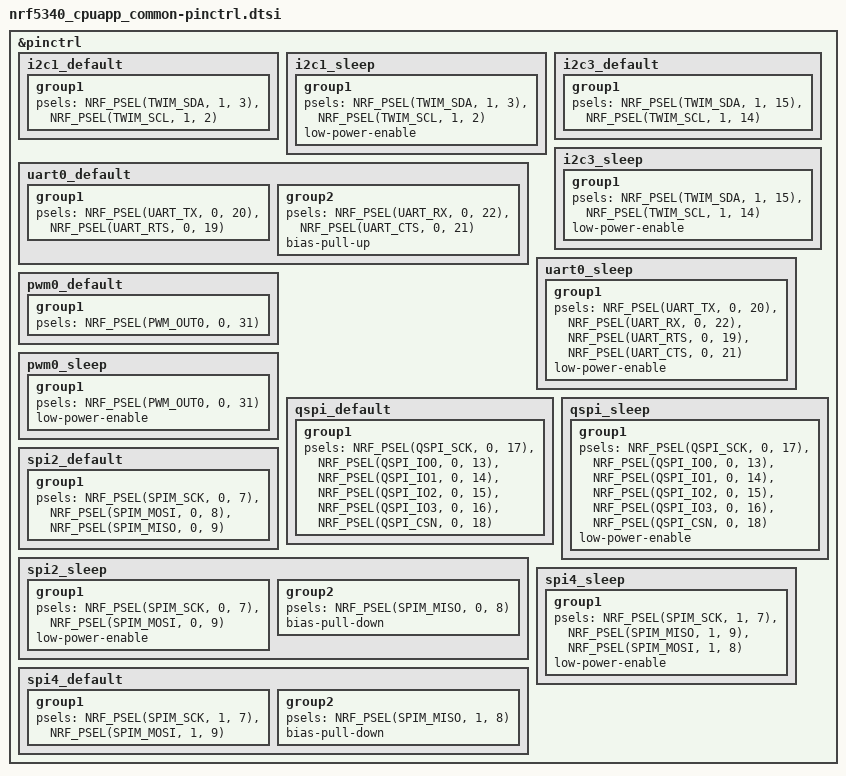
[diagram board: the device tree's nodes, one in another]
/*
 * Copyright (c) 2022 Nordic Semiconductor
 * SPDX-License-Identifier: Apache-2.0
 */

&pinctrl {
	i2c1_default: i2c1_default {
		group1 {
			psels = <NRF_PSEL(TWIM_SDA, 1, 3)>,
				<NRF_PSEL(TWIM_SCL, 1, 2)>;
		};
	};

	i2c1_sleep: i2c1_sleep {
		group1 {
			psels = <NRF_PSEL(TWIM_SDA, 1, 3)>,
				<NRF_PSEL(TWIM_SCL, 1, 2)>;
			low-power-enable;
		};
	};

	i2c3_default: i2c3_default {
		group1 {
			psels = <NRF_PSEL(TWIM_SDA, 1, 15)>,
				<NRF_PSEL(TWIM_SCL, 1, 14)>;
		};
	};

	i2c3_sleep: i2c3_sleep {
		group1 {
			psels = <NRF_PSEL(TWIM_SDA, 1, 15)>,
				<NRF_PSEL(TWIM_SCL, 1, 14)>;
			low-power-enable;
		};
	};

	uart0_default: uart0_default {
		group1 {
			psels = <NRF_PSEL(UART_TX, 0, 20)>,
				<NRF_PSEL(UART_RTS, 0, 19)>;
		};
		group2 {
			psels = <NRF_PSEL(UART_RX, 0, 22)>,
				<NRF_PSEL(UART_CTS, 0, 21)>;
			bias-pull-up;
		};
	};

	uart0_sleep: uart0_sleep {
		group1 {
			psels = <NRF_PSEL(UART_TX, 0, 20)>,
				<NRF_PSEL(UART_RX, 0, 22)>,
				<NRF_PSEL(UART_RTS, 0, 19)>,
				<NRF_PSEL(UART_CTS, 0, 21)>;
			low-power-enable;
		};
	};

	pwm0_default: pwm0_default {
		group1 {
			psels = <NRF_PSEL(PWM_OUT0, 0, 31)>;
		};
	};

	pwm0_sleep: pwm0_sleep {
		group1 {
			psels = <NRF_PSEL(PWM_OUT0, 0, 31)>;
			low-power-enable;
		};
	};

	qspi_default: qspi_default {
		group1 {
			psels = <NRF_PSEL(QSPI_SCK, 0, 17)>,
				<NRF_PSEL(QSPI_IO0, 0, 13)>,
				<NRF_PSEL(QSPI_IO1, 0, 14)>,
				<NRF_PSEL(QSPI_IO2, 0, 15)>,
				<NRF_PSEL(QSPI_IO3, 0, 16)>,
				<NRF_PSEL(QSPI_CSN, 0, 18)>;
		};
	};

	qspi_sleep: qspi_sleep {
		group1 {
			psels = <NRF_PSEL(QSPI_SCK, 0, 17)>,
				<NRF_PSEL(QSPI_IO0, 0, 13)>,
				<NRF_PSEL(QSPI_IO1, 0, 14)>,
				<NRF_PSEL(QSPI_IO2, 0, 15)>,
				<NRF_PSEL(QSPI_IO3, 0, 16)>,
				<NRF_PSEL(QSPI_CSN, 0, 18)>;
			low-power-enable;
		};
	};

	spi2_default: spi2_default {
		group1 {
			psels = <NRF_PSEL(SPIM_SCK, 0, 7)>,
				<NRF_PSEL(SPIM_MOSI, 0, 8)>,
				<NRF_PSEL(SPIM_MISO, 0, 9)>;
		};
	};

	spi2_sleep: spi2_sleep {
		group1 {
			psels = <NRF_PSEL(SPIM_SCK, 0, 7)>,
				<NRF_PSEL(SPIM_MOSI, 0, 9)>;
			low-power-enable;
		};
		group2 {
			psels = <NRF_PSEL(SPIM_MISO, 0, 8)>;
			bias-pull-down;
		};
	};

	spi4_default: spi4_default {
		group1 {
			psels = <NRF_PSEL(SPIM_SCK, 1, 7)>,
				<NRF_PSEL(SPIM_MOSI, 1, 9)>;
		};
		group2 {
			psels = <NRF_PSEL(SPIM_MISO, 1, 8)>;
			bias-pull-down;
		};
	};

	spi4_sleep: spi4_sleep {
		group1 {
			psels = <NRF_PSEL(SPIM_SCK, 1, 7)>,
				<NRF_PSEL(SPIM_MISO, 1, 9)>,
				<NRF_PSEL(SPIM_MOSI, 1, 8)>;
			low-power-enable;
		};
	};

};
